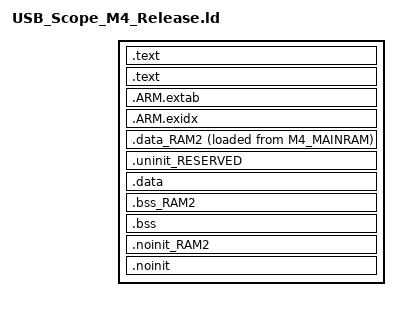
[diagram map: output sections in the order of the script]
/*
 * GENERATED FILE - DO NOT EDIT
 * (c) Code Red Technologies Ltd, 2008-2013
 * (c) NXP Semiconductors 2013-2017
 * Generated linker script file for LPC4370
 * Created from linkscript.ldt by FMCreateLinkLibraries
 * Using Freemarker v2.3.23
 * LPCXpresso v8.2.2 [Build 650] [2016-09-09]  on 2017/04/21 14:32:51
 */

INCLUDE "USB_Scope_M4_Release_library.ld"
INCLUDE "USB_Scope_M4_Release_memory.ld"

ENTRY(ResetISR)

SECTIONS
{
    /* MAIN TEXT SECTION */
    .text : ALIGN(4)
    {
        FILL(0xff)
        __vectors_start__ = ABSOLUTE(.) ;
        KEEP(*(.isr_vector))
        /* Global Section Table */
        . = ALIGN(4) ; 
        __section_table_start = .;
        __data_section_table = .;
        LONG(LOADADDR(.data));
        LONG(    ADDR(.data));
        LONG(  SIZEOF(.data));
        LONG(LOADADDR(.data_RAM2));
        LONG(    ADDR(.data_RAM2));
        LONG(  SIZEOF(.data_RAM2));
        __data_section_table_end = .;
        __bss_section_table = .;
        LONG(    ADDR(.bss));
        LONG(  SIZEOF(.bss));
        LONG(    ADDR(.bss_RAM2));
        LONG(  SIZEOF(.bss_RAM2));
        __bss_section_table_end = .;
        __section_table_end = . ;
	    /* End of Global Section Table */

        *(.after_vectors*)

    } >M4_MAINRAM

    .text : ALIGN(4)    
    {
        *(.text*)
        *(.rodata .rodata.* .constdata .constdata.*)
        . = ALIGN(4);
    } > M4_MAINRAM
    /*
     * for exception handling/unwind - some Newlib functions (in common
     * with C++ and STDC++) use this. 
     */
    .ARM.extab : ALIGN(4) 
    {
        *(.ARM.extab* .gnu.linkonce.armextab.*)
    } > M4_MAINRAM
    __exidx_start = .;

    .ARM.exidx : ALIGN(4)
    {
        *(.ARM.exidx* .gnu.linkonce.armexidx.*)
    } > M4_MAINRAM
    __exidx_end = .;

    _etext = .;
        
    /* DATA section for AHBRAM16KB */
    .data_RAM2 : ALIGN(4)
    {
        FILL(0xff)
        PROVIDE(__start_data_RAM2 = .) ;
        *(.ramfunc.$RAM2)
        *(.ramfunc.$AHBRAM16KB)
        *(.data.$RAM2*)
        *(.data.$AHBRAM16KB*)
        . = ALIGN(4) ;
        PROVIDE(__end_data_RAM2 = .) ;
     } > AHBRAM16KB AT>M4_MAINRAM

    /* MAIN DATA SECTION */
    .uninit_RESERVED : ALIGN(4)
    {
        KEEP(*(.bss.$RESERVED*))
        . = ALIGN(4) ;
        _end_uninit_RESERVED = .;
    } > M4_MAINRAM
    /* Main DATA section (M4_MAINRAM) */
    .data : ALIGN(4)
    {
       FILL(0xff)
       _data = . ;
       *(vtable)
       *(.ramfunc*)
       *(.data*)
       . = ALIGN(4) ;
       _edata = . ;
    } > M4_MAINRAM AT>M4_MAINRAM
    /* BSS section for AHBRAM16KB */
    .bss_RAM2 : ALIGN(4)
    {
       PROVIDE(__start_bss_RAM2 = .) ;
       *(.bss.$RAM2*)
       *(.bss.$AHBRAM16KB*)
       . = ALIGN (. != 0 ? 4 : 1) ; /* avoid empty segment */
       PROVIDE(__end_bss_RAM2 = .) ;
    } > AHBRAM16KB 
    /* MAIN BSS SECTION */
    .bss : ALIGN(4)
    {
        _bss = .;
        *(.bss*)
        *(COMMON)
        . = ALIGN(4) ;
        _ebss = .;
        PROVIDE(end = .);
    } > M4_MAINRAM
    /* NOINIT section for AHBRAM16KB */
    .noinit_RAM2 (NOLOAD) : ALIGN(4)
    {
       *(.noinit.$RAM2*)
       *(.noinit.$AHBRAM16KB*)
       . = ALIGN(4) ;
    } > AHBRAM16KB 
    /* DEFAULT NOINIT SECTION */
    .noinit (NOLOAD): ALIGN(4)
    {
        _noinit = .;
        *(.noinit*) 
         . = ALIGN(4) ;
        _end_noinit = .;
    } > M4_MAINRAM

    PROVIDE(_pvHeapStart = DEFINED(__user_heap_base) ? __user_heap_base : .);
    PROVIDE(_vStackTop = DEFINED(__user_stack_top) ? __user_stack_top : __top_M4_MAINRAM - 0);

    /* ## Create checksum value (used in startup) ## */
    PROVIDE(__valid_user_code_checksum = 0 - 
                                         (_vStackTop 
                                         + (ResetISR + 1) 
                                         + (NMI_Handler + 1) 
                                         + (HardFault_Handler + 1) 
                                         + (( DEFINED(MemManage_Handler) ? MemManage_Handler : 0 ) + 1)   /* MemManage_Handler may not be defined */
                                         + (( DEFINED(BusFault_Handler) ? BusFault_Handler : 0 ) + 1)     /* BusFault_Handler may not be defined */
                                         + (( DEFINED(UsageFault_Handler) ? UsageFault_Handler : 0 ) + 1) /* UsageFault_Handler may not be defined */
                                         ) );
}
